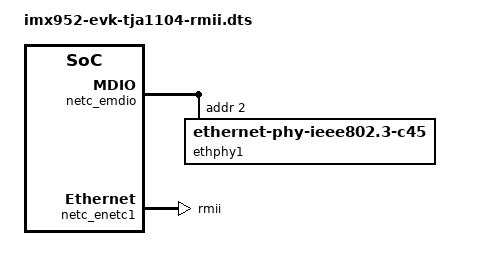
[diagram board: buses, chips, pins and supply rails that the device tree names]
// SPDX-License-Identifier: (GPL-2.0+ OR MIT)
/*
 * Copyright 2026 NXP
 */

/*
 * Notice:
 * 1. This file enables the RMII interface of ENETC1, so that ENETC1 port can
 *    work in RMII mode.
 * 2. When using the TJA1103/4 PHY chip, please complete the following
 *    hardware configuration on TJA1103/4 SRDB board.
 *    a) Short the 1-2 pins of CONFIG0 and CONFIG1 respectively, short the
 *       2-3 pins of CONFIG2, this will set the address of the PHY chip to 2.
 *    b) Short the 1-2 pins of CONFIG3 and disconnect the jumper of CONFIG4
 *       to enable the RMII mode of the PHY chip.
 *    c) Refer to the silk screen on the back of the daughter card, configure
 *       CONFIG5 and CONFIG6 according to the situation to set it as Master
 *       or Slave mode.
 *    d) Change the short circuit of R70 from 1-3 pins to 1-2 pins to use the
 *       correct RXER pin.
 *    e) Since the ENET IO pins of i.MX952 is using 1.8V voltage, please make
 *       sure that J17 jumper is shorted to 1-2 pins.
 *    f) Move R1214 to R1215 of i.MX952 EVK base board to use the correct RMII
 *       REF CLK pin. SoC provides 50MHz clock to PHY chip.
 *    g) Remove R1216 to reduce the interference on the ref clock pad.
 */

#include <dt-bindings/clock/nxp,imx95-clock.h>
#include "imx952-evk-tja1104-rgmii.dts"

/delete-node/ &ethphy1;

&netc_blk_ctrl {
	assigned-clocks = <&scmi_clk IMX952_CLK_ENET>,
			  <&scmi_clk IMX952_CLK_ENETREF>,
			  <&netcmix_blk_ctrl IMX95_CLK_NETCMIX_ENETC1_RMII>;
	assigned-clock-parents = <&scmi_clk IMX952_CLK_SYSPLL1_PFD1>,
				 <&scmi_clk IMX952_CLK_SYSPLL1_PFD0>,
				 <&scmi_clk IMX952_CLK_ENETREF>;
	assigned-clock-rates = <800000000>, <250000000>, <0>;
};

&netc_emdio {
	ethphy1: ethernet-phy@2 {
		compatible = "ethernet-phy-ieee802.3-c45";
		reg = <2>;
	};
};

&netc_enetc1 {
	phy-mode = "rmii";
};

&scmi_iomuxc {
	pinctrl_enetc1: enetc1grp {
		fsl,pins = <
			IMX952_PAD_ENET2_RD0__NETCMIX_TOP_ETH1_RMII_RXD0		0x50e
			IMX952_PAD_ENET2_RD1__NETCMIX_TOP_ETH1_RMII_RXD1		0x50e
			IMX952_PAD_ENET2_RD2__NETCMIX_TOP_ETH1_RMII_RX_ER		0x50e
			IMX952_PAD_ENET2_TX_CTL__NETCMIX_TOP_ETH1_RMII_TX_EN		0x50e
			IMX952_PAD_ENET2_RX_CTL__NETCMIX_TOP_ETH1_RMII_CRS_DV		0x50e
			IMX952_PAD_ENET2_TD0__NETCMIX_TOP_ETH1_RMII_TXD0		0x50e
			IMX952_PAD_ENET2_TD1__NETCMIX_TOP_ETH1_RMII_TXD1		0x50e
			IMX952_PAD_ENET2_TD2__NETCMIX_TOP_ETH1_RMII_REF50_CLK		0x4000058e
		>;
	};
};
